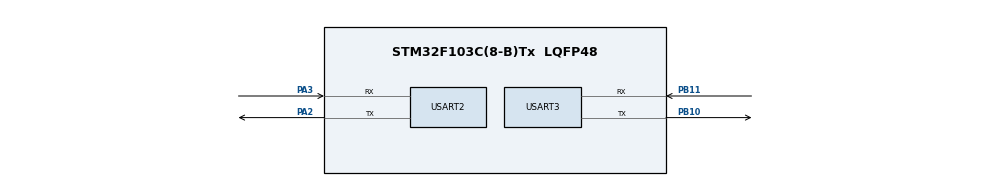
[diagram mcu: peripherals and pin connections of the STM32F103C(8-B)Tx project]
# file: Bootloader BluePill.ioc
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Mcu.Family=STM32F1
Mcu.Name=STM32F103C(8-B)Tx
Mcu.Package=LQFP48
NVIC.PriorityGroup=NVIC_PRIORITYGROUP_4
PA2.Mode=Asynchronous
PA2.Signal=USART2_TX
PA3.Mode=Asynchronous
PA3.Signal=USART2_RX
PB10.Mode=Asynchronous
PB10.Signal=USART3_TX
PB11.Mode=Asynchronous
PB11.Signal=USART3_RX
ProjectManager.HeapSize=0x200
ProjectManager.StackSize=0x400
ProjectManager.TargetToolchain=MDK-ARM V5
RCC.APB1Freq_Value=8000000
RCC.APB2Freq_Value=8000000
USART2.VirtualMode=VM_ASYNC
USART3.VirtualMode=VM_ASYNC
VP_CRC_VS_CRC.Mode=CRC_Activate
VP_SYS_VS_ND.Mode=No_Debug
board=custom

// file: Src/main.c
/* USER CODE BEGIN Header */
/**
  ******************************************************************************
  * @file           : main.c
  * @brief          : Main program body
  ******************************************************************************
  * @attention
  *
  * <h2><center>&copy; Copyright (c) 2020 STMicroelectronics.
  * All rights reserved.</center></h2>
  *
  * This software component is licensed by ST under BSD 3-Clause license,
  * the "License"; You may not use this file except in compliance with the
  * License. You may obtain a copy of the License at:
  *                        opensource.org/licenses/BSD-3-Clause
  *
  ******************************************************************************
  */
/* USER CODE END Header */

#include "main.h"

CRC_HandleTypeDef hcrc;

UART_HandleTypeDef huart2;
UART_HandleTypeDef huart3;

void SystemClock_Config(void);
static void MX_GPIO_Init(void);
static void MX_CRC_Init(void);
static void MX_USART2_UART_Init(void);
static void MX_USART3_UART_Init(void);
/* USER CODE BEGIN PFP */
char data1[] = "Running Bootloader \r\n";
char data2[] = "Going to User app \r\n";
/* USER CODE END PFP */

int main(void)
{

  /* MCU Configuration--------------------------------------------------------*/

  /* Reset of all peripherals, Initializes the Flash interface and the Systick. */
  HAL_Init();

  /* Configure the system clock */
  SystemClock_Config();

  /* Initialize all configured peripherals */
  MX_GPIO_Init();
  MX_CRC_Init();
  MX_USART2_UART_Init();
  MX_USART3_UART_Init();

  /* Infinite loop */
  while (1)
  {

		//HAL_UART_Transmit(&huart2, (uint8_t*)somedata, sizeof(somedata), HAL_MAX_DELAY);
		//uint32_t current_tick = HAL_GetTick();
		//while (HAL_GetTick() <= (current_tick + 500));

		HAL_GPIO_TogglePin(GPIOA, GPIO_PIN_12);
		HAL_Delay(500);

  }
}

void SystemClock_Config(void)
{
  RCC_OscInitTypeDef RCC_OscInitStruct = {0};
  RCC_ClkInitTypeDef RCC_ClkInitStruct = {0};

  /** Initializes the CPU, AHB and APB busses clocks
  */
  RCC_OscInitStruct.OscillatorType = RCC_OSCILLATORTYPE_HSI;
  RCC_OscInitStruct.HSIState = RCC_HSI_ON;
  RCC_OscInitStruct.HSICalibrationValue = RCC_HSICALIBRATION_DEFAULT;
  RCC_OscInitStruct.PLL.PLLState = RCC_PLL_NONE;
  if (HAL_RCC_OscConfig(&RCC_OscInitStruct) != HAL_OK)
  {
    Error_Handler();
  }
  /** Initializes the CPU, AHB and APB busses clocks
  */
  RCC_ClkInitStruct.ClockType = RCC_CLOCKTYPE_HCLK|RCC_CLOCKTYPE_SYSCLK
                              |RCC_CLOCKTYPE_PCLK1|RCC_CLOCKTYPE_PCLK2;
  RCC_ClkInitStruct.SYSCLKSource = RCC_SYSCLKSOURCE_HSI;
  RCC_ClkInitStruct.AHBCLKDivider = RCC_SYSCLK_DIV1;
  RCC_ClkInitStruct.APB1CLKDivider = RCC_HCLK_DIV1;
  RCC_ClkInitStruct.APB2CLKDivider = RCC_HCLK_DIV1;

  if (HAL_RCC_ClockConfig(&RCC_ClkInitStruct, FLASH_LATENCY_0) != HAL_OK)
  {
    Error_Handler();
  }
}

static void MX_CRC_Init(void)
{

  hcrc.Instance = CRC;
  if (HAL_CRC_Init(&hcrc) != HAL_OK)
  {
    Error_Handler();
  }

}

static void MX_USART2_UART_Init(void)
{

  huart2.Instance = USART2;
  huart2.Init.BaudRate = 115200;
  huart2.Init.WordLength = UART_WORDLENGTH_8B;
  huart2.Init.StopBits = UART_STOPBITS_1;
  huart2.Init.Parity = UART_PARITY_NONE;
  huart2.Init.Mode = UART_MODE_TX_RX;
  huart2.Init.HwFlowCtl = UART_HWCONTROL_NONE;
  huart2.Init.OverSampling = UART_OVERSAMPLING_16;
  if (HAL_UART_Init(&huart2) != HAL_OK)
  {
    Error_Handler();
  }

}

static void MX_USART3_UART_Init(void)
{

  huart3.Instance = USART3;
  huart3.Init.BaudRate = 115200;
  huart3.Init.WordLength = UART_WORDLENGTH_8B;
  huart3.Init.StopBits = UART_STOPBITS_1;
  huart3.Init.Parity = UART_PARITY_NONE;
  huart3.Init.Mode = UART_MODE_TX_RX;
  huart3.Init.HwFlowCtl = UART_HWCONTROL_NONE;
  huart3.Init.OverSampling = UART_OVERSAMPLING_16;
  if (HAL_UART_Init(&huart3) != HAL_OK)
  {
    Error_Handler();
  }

}

static void MX_GPIO_Init(void)
{

  /* GPIO Ports Clock Enable */
  __HAL_RCC_GPIOA_CLK_ENABLE();
  __HAL_RCC_GPIOB_CLK_ENABLE();

}

void Error_Handler(void)
{
}

/************************ (C) COPYRIGHT STMicroelectronics *****END OF FILE****/
